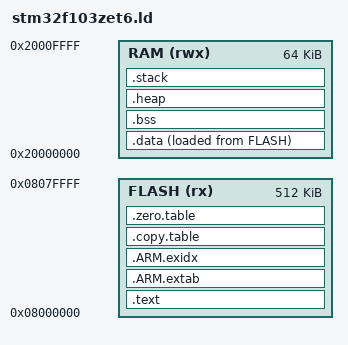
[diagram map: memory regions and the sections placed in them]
/**
*********************************************************************************************************
* @file   : stm32f103zet6_flash.ld
* @author : tuwenbo
* @date   : 16 Nov 2024
* @brief  : Linker script for STM32F103ZET6 Cortex-M3 ARM MCU.
*
*********************************************************************************************************
*/

__STACK_SIZE = 0x00000400;/* 1KB */
__HEAP_SIZE  = 0x00001000;/* 4KB */

MEMORY
{
  FLASH (rx) : ORIGIN = 0x08000000, LENGTH = 512K
  RAM (rwx)  : ORIGIN = 0x20000000, LENGTH = 64K
}

/* Linker script to place sections and symbol values. Should be used together
 * with other linker script that defines memory regions FLASH and RAM.
 * It references following symbols, which must be defined in code:
 *   Reset_Handler : Entry of reset handler
 *
 * It defines following symbols, which code can use without definition:
 *   __exidx_start
 *   __exidx_end
 *   __copy_table_start__
 *   __copy_table_end__
 *   __zero_table_start__
 *   __zero_table_end__
 *   __etext          (deprecated)
 *   __data_start__
 *   __preinit_array_start
 *   __preinit_array_end
 *   __init_array_start
 *   __init_array_end
 *   __fini_array_start
 *   __fini_array_end
 *   __data_end__
 *   __bss_start__
 *   __bss_end__
 *   __end__
 *   end
 *   __HeapLimit
 *   __StackLimit
 *   __StackTop
 *   __stack
 */

/* Entry Point */
ENTRY(Reset_Handler)

SECTIONS
{
  .text :
  {
    /* The startup code goes first into FLASH */
    KEEP(*(.vectors))
    *(.text*)

    KEEP(*(.init))
    KEEP(*(.fini))

    /* .ctors */
    *crtbegin.o(.ctors)
    *crtbegin?.o(.ctors)
    *(EXCLUDE_FILE(*crtend?.o *crtend.o) .ctors)
    *(SORT(.ctors.*))
    *(.ctors)

    /* .dtors */
    *crtbegin.o(.dtors)
    *crtbegin?.o(.dtors)
    *(EXCLUDE_FILE(*crtend?.o *crtend.o) .dtors)
    *(SORT(.dtors.*))
    *(.dtors)

    *(.rodata*)

    KEEP(*(.eh_frame*))
  } > FLASH

  /*
   * SG veneers:
   * All SG veneers are placed in the special output section .gnu.sgstubs. Its start address
   * must be set, either with the command line option '--section-start' or in a linker script,
   * to indicate where to place these veneers in memory.
   */
/*
  .gnu.sgstubs :
  {
    . = ALIGN(32);
  } > FLASH
*/
  .ARM.extab :
  {
    *(.ARM.extab* .gnu.linkonce.armextab.*)
  } > FLASH

  __exidx_start = .;
  .ARM.exidx :
  {
    *(.ARM.exidx* .gnu.linkonce.armexidx.*)
  } > FLASH
  __exidx_end = .;

  .copy.table :
  {
    . = ALIGN(4);
    __copy_table_start__ = .;

    LONG (LOADADDR(.data))
    LONG (ADDR(.data))
    LONG (SIZEOF(.data) / 4)

    /* Add each additional data section here */
/*
    LONG (LOADADDR(.data2))
    LONG (ADDR(.data2))
    LONG (SIZEOF(.data2) / 4)
*/
    __copy_table_end__ = .;
  } > FLASH

  .zero.table :
  {
    . = ALIGN(4);
    __zero_table_start__ = .;

/*  .bss initialization to zero is already done during C Run-Time Startup.
    LONG (ADDR(.bss))
    LONG (SIZEOF(.bss) / 4)
*/

    /* Add each additional bss section here */
/*
    LONG (ADDR(.bss2))
    LONG (SIZEOF(.bss2) / 4)
*/
    __zero_table_end__ = .;
  } > FLASH

  /*
   * This __etext variable is kept for backward compatibility with older,
   * ASM based startup files.
   */
  PROVIDE(__etext = LOADADDR(.data));

  .data : ALIGN(4)
  {
    __data_start__ = .;
    *(vtable)
    *(.data)
    *(.data.*)

    . = ALIGN(4);
    /* preinit data */
    PROVIDE_HIDDEN (__preinit_array_start = .);
    KEEP(*(.preinit_array))
    PROVIDE_HIDDEN (__preinit_array_end = .);

    . = ALIGN(4);
    /* init data */
    PROVIDE_HIDDEN (__init_array_start = .);
    KEEP(*(SORT(.init_array.*)))
    KEEP(*(.init_array))
    PROVIDE_HIDDEN (__init_array_end = .);

    . = ALIGN(4);
    /* finit data */
    PROVIDE_HIDDEN (__fini_array_start = .);
    KEEP(*(SORT(.fini_array.*)))
    KEEP(*(.fini_array))
    PROVIDE_HIDDEN (__fini_array_end = .);

    KEEP(*(.jcr*))
    . = ALIGN(4);
    /* All data end */
    __data_end__ = .;

  } > RAM AT > FLASH

  /*
   * Secondary data section, optional
   *
   * Remember to add each additional data section
   * to the .copy.table above to assure proper
   * initialization during startup.
   */
/*
  .data2 : ALIGN(4)
  {
    . = ALIGN(4);
    __data2_start__ = .;
    *(.data2)
    *(.data2.*)
    . = ALIGN(4);
    __data2_end__ = .;

  } > RAM2 AT > FLASH
*/

  .bss :
  {
    . = ALIGN(4);
    __bss_start__ = .;
    *(.bss)
    *(.bss.*)
    *(COMMON)
    . = ALIGN(4);
    __bss_end__ = .;
  } > RAM AT > RAM

  /*
   * Secondary bss section, optional
   *
   * Remember to add each additional bss section
   * to the .zero.table above to assure proper
   * initialization during startup.
   */
/*
  .bss2 :
  {
    . = ALIGN(4);
    __bss2_start__ = .;
    *(.bss2)
    *(.bss2.*)
    . = ALIGN(4);
    __bss2_end__ = .;
  } > RAM2 AT > RAM2
*/

  .heap (COPY) :
  {
    . = ALIGN(8);
    __end__ = .;
    PROVIDE(end = .);
    . = . + __HEAP_SIZE;
    . = ALIGN(8);
    __HeapLimit = .;
  } > RAM

  .stack (ORIGIN(RAM) + LENGTH(RAM) - __STACK_SIZE) (COPY) :
  {
    . = ALIGN(8);
    __StackLimit = .;
    . = . + __STACK_SIZE;
    . = ALIGN(8);
    __StackTop = .;
  } > RAM
  PROVIDE(__stack = __StackTop);

  /* Check if data + heap + stack exceeds RAM limit */
  ASSERT(__StackLimit >= __HeapLimit, "region RAM overflowed with stack")
}
